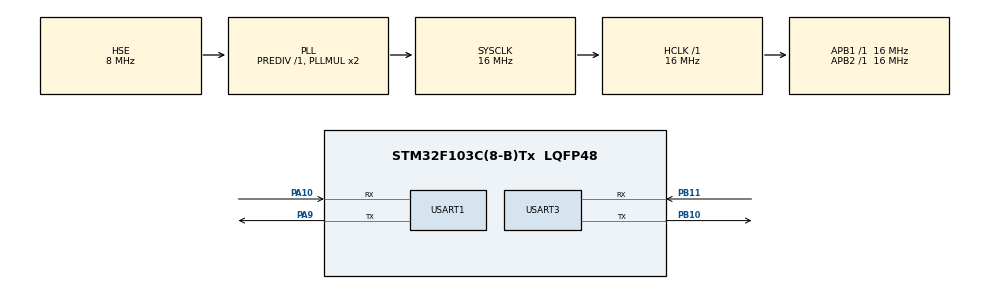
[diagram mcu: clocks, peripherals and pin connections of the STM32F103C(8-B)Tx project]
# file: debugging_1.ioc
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Dma.Request0=USART1_TX
Dma.Request1=USART3_RX
Dma.Request2=USART3_TX
Dma.Request3=USART1_RX
Dma.USART1_RX.3.Direction=DMA_PERIPH_TO_MEMORY
Dma.USART1_RX.3.Instance=DMA1_Channel5
Dma.USART1_RX.3.MemDataAlignment=DMA_MDATAALIGN_BYTE
Dma.USART1_RX.3.MemInc=DMA_MINC_ENABLE
Dma.USART1_RX.3.Mode=DMA_CIRCULAR
Dma.USART1_RX.3.PeriphDataAlignment=DMA_PDATAALIGN_BYTE
Dma.USART1_RX.3.PeriphInc=DMA_PINC_DISABLE
Dma.USART1_RX.3.Priority=DMA_PRIORITY_LOW
Dma.USART1_TX.0.Direction=DMA_MEMORY_TO_PERIPH
Dma.USART1_TX.0.Instance=DMA1_Channel4
Dma.USART1_TX.0.MemDataAlignment=DMA_MDATAALIGN_BYTE
Dma.USART1_TX.0.MemInc=DMA_MINC_ENABLE
Dma.USART1_TX.0.Mode=DMA_CIRCULAR
Dma.USART1_TX.0.PeriphDataAlignment=DMA_PDATAALIGN_BYTE
Dma.USART1_TX.0.PeriphInc=DMA_PINC_DISABLE
Dma.USART1_TX.0.Priority=DMA_PRIORITY_LOW
Dma.USART3_RX.1.Direction=DMA_PERIPH_TO_MEMORY
Dma.USART3_RX.1.Instance=DMA1_Channel3
Dma.USART3_RX.1.MemDataAlignment=DMA_MDATAALIGN_BYTE
Dma.USART3_RX.1.MemInc=DMA_MINC_ENABLE
Dma.USART3_RX.1.Mode=DMA_CIRCULAR
Dma.USART3_RX.1.PeriphDataAlignment=DMA_PDATAALIGN_BYTE
Dma.USART3_RX.1.PeriphInc=DMA_PINC_DISABLE
Dma.USART3_RX.1.Priority=DMA_PRIORITY_LOW
Dma.USART3_TX.2.Direction=DMA_MEMORY_TO_PERIPH
Dma.USART3_TX.2.Instance=DMA1_Channel2
Dma.USART3_TX.2.MemDataAlignment=DMA_MDATAALIGN_BYTE
Dma.USART3_TX.2.MemInc=DMA_MINC_ENABLE
Dma.USART3_TX.2.Mode=DMA_CIRCULAR
Dma.USART3_TX.2.PeriphDataAlignment=DMA_PDATAALIGN_BYTE
Dma.USART3_TX.2.PeriphInc=DMA_PINC_DISABLE
Dma.USART3_TX.2.Priority=DMA_PRIORITY_LOW
Mcu.Family=STM32F1
Mcu.Name=STM32F103C(8-B)Tx
Mcu.Package=LQFP48
NVIC.DMA1_Channel2_IRQn=true\:0\:0\:false\:false\:true\:false\:true\:true
NVIC.DMA1_Channel3_IRQn=true\:0\:0\:false\:false\:true\:false\:true\:true
NVIC.DMA1_Channel4_IRQn=true\:0\:0\:false\:false\:true\:false\:true\:true
NVIC.DMA1_Channel5_IRQn=true\:0\:0\:false\:false\:true\:false\:true\:true
NVIC.PriorityGroup=NVIC_PRIORITYGROUP_4
NVIC.USART1_IRQn=true\:0\:0\:false\:false\:true\:true\:true\:true
NVIC.USART3_IRQn=true\:0\:0\:false\:false\:true\:true\:true\:true
PA10.Mode=Asynchronous
PA10.Signal=USART1_RX
PA9.Mode=Asynchronous
PA9.Signal=USART1_TX
PB10.Mode=Asynchronous
PB10.Signal=USART3_TX
PB11.Mode=Asynchronous
PB11.Signal=USART3_RX
PD0-OSC_IN.Mode=HSE-External-Oscillator
PD0-OSC_IN.Signal=RCC_OSC_IN
PD1-OSC_OUT.Mode=HSE-External-Oscillator
PD1-OSC_OUT.Signal=RCC_OSC_OUT
ProjectManager.HeapSize=0x200
ProjectManager.StackSize=0x400
ProjectManager.TargetToolchain=STM32CubeIDE
RCC.AHBFreq_Value=16000000
RCC.APB1Freq_Value=16000000
RCC.APB1TimFreq_Value=16000000
RCC.APB2Freq_Value=16000000
RCC.APB2TimFreq_Value=16000000
RCC.HCLKFreq_Value=16000000
RCC.PLLSourceVirtual=RCC_PLLSOURCE_HSE
RCC.SYSCLKFreq_VALUE=16000000
RCC.SYSCLKSource=RCC_SYSCLKSOURCE_PLLCLK
RCC.USBFreq_Value=16000000
USART1.VirtualMode=VM_ASYNC
USART3.VirtualMode=VM_ASYNC
VP_SYS_VS_ND.Mode=No_Debug
board=custom

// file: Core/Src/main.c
/* USER CODE BEGIN Header */
/**
  ******************************************************************************
  * @file           : main.c
  * @brief          : Main program body
  ******************************************************************************
  * @attention
  *
  * Copyright (c) 2025 STMicroelectronics.
  * All rights reserved.
  *
  * This software is licensed under terms that can be found in the LICENSE file
  * in the root directory of this software component.
  * If no LICENSE file comes with this software, it is provided AS-IS.
  *
  ******************************************************************************
  */
/* USER CODE END Header */
#include "main.h"

/* USER CODE BEGIN Includes */
#include <string.h>
#include <stdio.h>
/* USER CODE END Includes */

UART_HandleTypeDef huart1;
UART_HandleTypeDef huart3;
DMA_HandleTypeDef hdma_usart1_tx;
DMA_HandleTypeDef hdma_usart1_rx;
DMA_HandleTypeDef hdma_usart3_rx;
DMA_HandleTypeDef hdma_usart3_tx;

/* USER CODE BEGIN PV */
uint8_t rx3Buff[64] = {0};
uint8_t tx1Buff[64] = {0};
//uint8_t rx3Buff;
/* USER CODE END PV */

void SystemClock_Config(void);
static void MX_GPIO_Init(void);
static void MX_DMA_Init(void);
static void MX_USART1_UART_Init(void);
static void MX_USART3_UART_Init(void);

/* USER CODE BEGIN 0 */
//void HAL_UART_RxCpltCallback(UART_HandleTypeDef *huart) {
////	char debug[64];
////	int len = sprintf(debug, "contact message=%d\r\n", rx3Buff);
////	HAL_UART_Transmit(&huart1, (uint8_t*)debug, len, HAL_MAX_DELAY);
//	HAL_UART_Transmit_IT(&huart1, rx3Buff, sizeof(rx3Buff));
//
//	HAL_UART_Receive_IT(&huart3, rx3Buff, sizeof(rx3Buff));
//}

void HAL_UARTEx_RxEventCallback(UART_HandleTypeDef *huart, uint16_t Size) {
	if (huart->Instance == USART3) {
		memcpy(tx1Buff, rx3Buff, Size);
		HAL_UART_Transmit(&huart1, tx1Buff, Size, 100);
		//memset(rx3Buff, 0, sizeof(rx3Buff));
		//HAL_UARTEx_ReceiveToIdle_DMA(&huart3, rx3Buff, sizeof(rx3Buff));
	}
}
/* USER CODE END 0 */

int main(void)
{

  /* MCU Configuration--------------------------------------------------------*/

  /* Reset of all peripherals, Initializes the Flash interface and the Systick. */
  HAL_Init();

  /* Configure the system clock */
  SystemClock_Config();

  /* Initialize all configured peripherals */
  MX_GPIO_Init();
  MX_DMA_Init();
  MX_USART1_UART_Init();
  MX_USART3_UART_Init();
  /* USER CODE BEGIN 2 */
//  HAL_UART_Receive_IT(&huart3, rx3Buff, sizeof(rx3Buff));
  HAL_UARTEx_ReceiveToIdle_DMA(&huart3, rx3Buff, sizeof(rx3Buff));
  /* USER CODE END 2 */

  /* Infinite loop */
  while (1)
  {

  }
}

void SystemClock_Config(void)
{
  RCC_OscInitTypeDef RCC_OscInitStruct = {0};
  RCC_ClkInitTypeDef RCC_ClkInitStruct = {0};

  /** Initializes the RCC Oscillators according to the specified parameters
  * in the RCC_OscInitTypeDef structure.
  */
  RCC_OscInitStruct.OscillatorType = RCC_OSCILLATORTYPE_HSE;
  RCC_OscInitStruct.HSEState = RCC_HSE_ON;
  RCC_OscInitStruct.HSEPredivValue = RCC_HSE_PREDIV_DIV1;
  RCC_OscInitStruct.HSIState = RCC_HSI_ON;
  RCC_OscInitStruct.PLL.PLLState = RCC_PLL_ON;
  RCC_OscInitStruct.PLL.PLLSource = RCC_PLLSOURCE_HSE;
  RCC_OscInitStruct.PLL.PLLMUL = RCC_PLL_MUL2;
  if (HAL_RCC_OscConfig(&RCC_OscInitStruct) != HAL_OK)
  {
    Error_Handler();
  }

  /** Initializes the CPU, AHB and APB buses clocks
  */
  RCC_ClkInitStruct.ClockType = RCC_CLOCKTYPE_HCLK|RCC_CLOCKTYPE_SYSCLK
                              |RCC_CLOCKTYPE_PCLK1|RCC_CLOCKTYPE_PCLK2;
  RCC_ClkInitStruct.SYSCLKSource = RCC_SYSCLKSOURCE_PLLCLK;
  RCC_ClkInitStruct.AHBCLKDivider = RCC_SYSCLK_DIV1;
  RCC_ClkInitStruct.APB1CLKDivider = RCC_HCLK_DIV1;
  RCC_ClkInitStruct.APB2CLKDivider = RCC_HCLK_DIV1;

  if (HAL_RCC_ClockConfig(&RCC_ClkInitStruct, FLASH_LATENCY_0) != HAL_OK)
  {
    Error_Handler();
  }
}

static void MX_USART1_UART_Init(void)
{

  huart1.Instance = USART1;
  huart1.Init.BaudRate = 115200;
  huart1.Init.WordLength = UART_WORDLENGTH_8B;
  huart1.Init.StopBits = UART_STOPBITS_1;
  huart1.Init.Parity = UART_PARITY_NONE;
  huart1.Init.Mode = UART_MODE_TX_RX;
  huart1.Init.HwFlowCtl = UART_HWCONTROL_NONE;
  huart1.Init.OverSampling = UART_OVERSAMPLING_16;
  if (HAL_UART_Init(&huart1) != HAL_OK)
  {
    Error_Handler();
  }

}

static void MX_USART3_UART_Init(void)
{

  huart3.Instance = USART3;
  huart3.Init.BaudRate = 115200;
  huart3.Init.WordLength = UART_WORDLENGTH_8B;
  huart3.Init.StopBits = UART_STOPBITS_1;
  huart3.Init.Parity = UART_PARITY_NONE;
  huart3.Init.Mode = UART_MODE_TX_RX;
  huart3.Init.HwFlowCtl = UART_HWCONTROL_NONE;
  huart3.Init.OverSampling = UART_OVERSAMPLING_16;
  if (HAL_UART_Init(&huart3) != HAL_OK)
  {
    Error_Handler();
  }

}

static void MX_DMA_Init(void)
{

  /* DMA controller clock enable */
  __HAL_RCC_DMA1_CLK_ENABLE();

  /* DMA interrupt init */
  /* DMA1_Channel2_IRQn interrupt configuration */
  HAL_NVIC_SetPriority(DMA1_Channel2_IRQn, 0, 0);
  HAL_NVIC_EnableIRQ(DMA1_Channel2_IRQn);
  /* DMA1_Channel3_IRQn interrupt configuration */
  HAL_NVIC_SetPriority(DMA1_Channel3_IRQn, 0, 0);
  HAL_NVIC_EnableIRQ(DMA1_Channel3_IRQn);
  /* DMA1_Channel4_IRQn interrupt configuration */
  HAL_NVIC_SetPriority(DMA1_Channel4_IRQn, 0, 0);
  HAL_NVIC_EnableIRQ(DMA1_Channel4_IRQn);
  /* DMA1_Channel5_IRQn interrupt configuration */
  HAL_NVIC_SetPriority(DMA1_Channel5_IRQn, 0, 0);
  HAL_NVIC_EnableIRQ(DMA1_Channel5_IRQn);

}

static void MX_GPIO_Init(void)
{

  /* GPIO Ports Clock Enable */
  __HAL_RCC_GPIOD_CLK_ENABLE();
  __HAL_RCC_GPIOB_CLK_ENABLE();
  __HAL_RCC_GPIOA_CLK_ENABLE();

}

void Error_Handler(void)
{
  __disable_irq();
  while (1)
  {
  }
}
